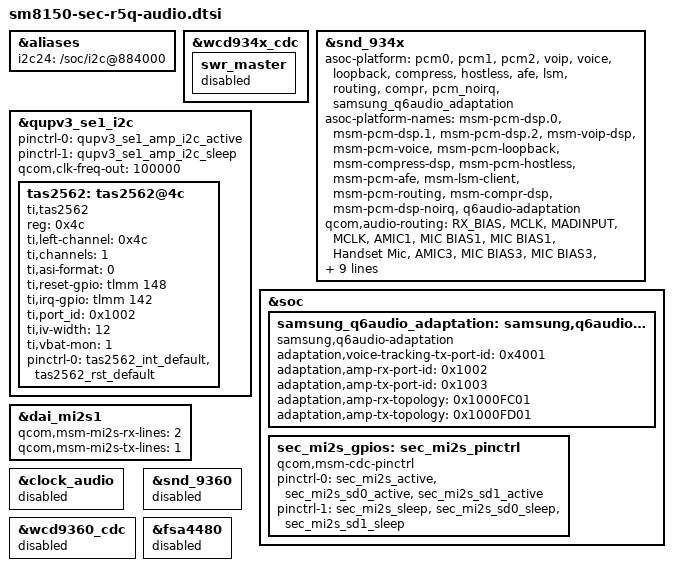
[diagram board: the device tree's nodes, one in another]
/* Copyright (c) 2016-2017, The Linux Foundation. All rights reserved.
 *
 * This program is free software; you can redistribute it and/or modify
 * it under the terms of the GNU General Public License version 2 and
 * only version 2 as published by the Free Software Foundation.
 *
 * This program is distributed in the hope that it will be useful,
 * but WITHOUT ANY WARRANTY; without even the implied warranty of
 * MERCHANTABILITY or FITNESS FOR A PARTICULAR PURPOSE.  See the
 * GNU General Public License for more details.
 */

#include "../qcom/sm8150-audio-overlay.dtsi"

&aliases {
	i2c24 = "/soc/i2c@884000";
};

&wcd934x_cdc {
	swr_master {
		status = "disabled";
	};
};

&snd_934x {
	asoc-platform = <&pcm0>, <&pcm1>, <&pcm2>, <&voip>, <&voice>,
			<&loopback>, <&compress>, <&hostless>,
			<&afe>, <&lsm>, <&routing>, <&compr>,
			<&pcm_noirq>, <&samsung_q6audio_adaptation>;
	asoc-platform-names = "msm-pcm-dsp.0", "msm-pcm-dsp.1",
			"msm-pcm-dsp.2", "msm-voip-dsp",
			"msm-pcm-voice", "msm-pcm-loopback",
			"msm-compress-dsp", "msm-pcm-hostless",
			"msm-pcm-afe", "msm-lsm-client",
			"msm-pcm-routing", "msm-compr-dsp",
			"msm-pcm-dsp-noirq", "q6audio-adaptation";
	qcom,audio-routing =
		"RX_BIAS", "MCLK",
		"MADINPUT", "MCLK",
		"AMIC1", "MIC BIAS1",
		"MIC BIAS1", "Handset Mic",
		"AMIC3", "MIC BIAS3",
		"MIC BIAS3", "Sub Mic",
		"AMIC4", "MIC BIAS4",
		"MIC BIAS4", "3rd Mic",
		"AMIC2", "MIC BIAS2",
		"MIC BIAS2", "4th Mic";
	qcom,wcn-btfm = <1>;
	qcom,hph-en1-gpio = <0>;
	qcom,hph-en0-gpio = <0>;
	fsa4480-i2c-handle = <0>;
	qcom,wsa-max-devs = <0>;

	qcom,sec-mi2s-gpios = <&sec_mi2s_gpios>;
};

&qupv3_se1_i2c {
	pinctrl-names = "default", "sleep";
	pinctrl-0 = <&qupv3_se1_amp_i2c_active>;
	pinctrl-1 = <&qupv3_se1_amp_i2c_sleep>;
	qcom,clk-freq-out = <100000>;
	status = "ok";

	tas2562:tas2562@4c {
		#sound-dai-cells = <0>;
		compatible = "ti,tas2562";
		reg = <0x4c>;
		ti,left-channel = <0x4c>;
		ti,channels = <1>;
		ti,asi-format = <0>;
		ti,reset-gpio = <&tlmm 148 0>;
		ti,irq-gpio = <&tlmm 142 0>;
		ti,port_id = <0x1002>;
		ti,iv-width = <12>;
		ti,vbat-mon = <1>;
		status = "ok";

		pinctrl-names = "default";
		pinctrl-0 = <&tas2562_int_default &tas2562_rst_default>;
	};
};

&soc {
	samsung_q6audio_adaptation: samsung,q6audio-adaptation {
		compatible = "samsung,q6audio-adaptation";
		adaptation,voice-tracking-tx-port-id = <0x4001>;
		adaptation,amp-rx-port-id = <0x1002>;
		adaptation,amp-tx-port-id = <0x1003>;
		adaptation,amp-rx-topology = <0x1000FC01>;
		adaptation,amp-tx-topology = <0x1000FD01>;
	};

	sec_mi2s_gpios: sec_mi2s_pinctrl {
		compatible = "qcom,msm-cdc-pinctrl";
		pinctrl-names = "aud_active", "aud_sleep";
		pinctrl-0 = <&sec_mi2s_active &sec_mi2s_sd0_active
				&sec_mi2s_sd1_active>;
		pinctrl-1 = <&sec_mi2s_sleep &sec_mi2s_sd0_sleep
				&sec_mi2s_sd1_sleep>;
	};
};

&dai_mi2s1 {
	qcom,msm-mi2s-rx-lines = <2>;
	qcom,msm-mi2s-tx-lines = <1>;
};

&clock_audio {
	status = "disabled";
};

&wcd9360_cdc {
	status = "disabled";
};

&snd_9360 {
	status = "disabled";
};

&fsa4480 {
	status = "disabled";
};
